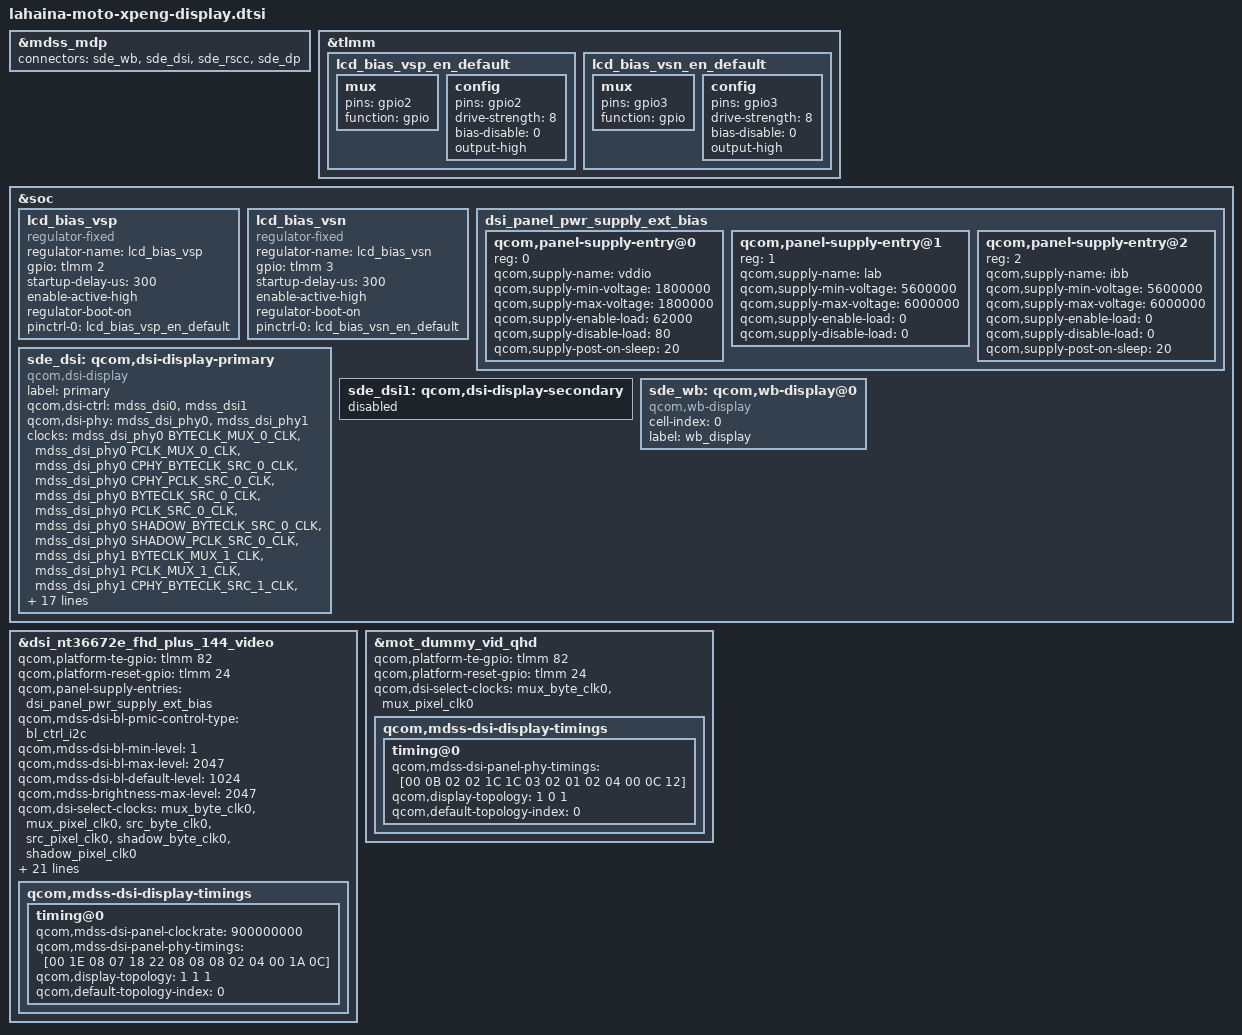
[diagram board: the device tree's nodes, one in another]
/* Copyright (c) 2019, The Linux Foundation. All rights reserved.
 *
 * This program is free software; you can redistribute it and/or modify
 * it under the terms of the GNU General Public License version 2 and
 * only version 2 as published by the Free Software Foundation.
 *
 * This program is distributed in the hope that it will be useful,
 * but WITHOUT ANY WARRANTY; without even the implied warranty of
 * MERCHANTABILITY or FITNESS FOR A PARTICULAR PURPOSE.  See the
 * GNU General Public License for more details.
 */

#include <dt-bindings/clock/mdss-5nm-pll-clk.h>
#include "dsi-panel-mot-tiamma-nt36672e-678-1080p-video-common.dtsi"
#include "dsi-panel-mot-dummy-qhd-video.dtsi"

&mdss_mdp {
	connectors = <&sde_wb &sde_dsi &sde_rscc &sde_dp>;
};


&tlmm {
	lcd_bias_vsp_en_default: lcd_bias_vsp_en_default {
		mux {
			pins = "gpio2";
			function = "gpio";
		};

		config {
			pins = "gpio2";
			drive-strength = <8>;
			bias-disable = <0>;
			output-high;
		};
	};

	lcd_bias_vsn_en_default: lcd_bias_vsn_en_default {
		mux {
			pins = "gpio3";
			function = "gpio";
		};

		config {
			pins = "gpio3";
			drive-strength = <8>;
			bias-disable = <0>;
			output-high;
		};
	};
};

&soc {
	lcd_bias_vsp: lcd_bias_vsp {
		compatible = "regulator-fixed";
		regulator-name = "lcd_bias_vsp";
		gpio = <&tlmm 2 0>;
		startup-delay-us = <300>;
		enable-active-high;
		regulator-boot-on;
		pinctrl-names = "default";
		pinctrl-0 = <&lcd_bias_vsp_en_default>;
	};

	lcd_bias_vsn: lcd_bias_vsn {
		compatible = "regulator-fixed";
		regulator-name = "lcd_bias_vsn";
		gpio = <&tlmm 3 0>;
		startup-delay-us = <300>;
		enable-active-high;
		regulator-boot-on;
		pinctrl-names = "default";
		pinctrl-0 = <&lcd_bias_vsn_en_default>;
	};

        dsi_panel_pwr_supply_ext_bias: dsi_panel_pwr_supply_ext_bias {
                #address-cells = <1>;
                #size-cells = <0>;

                qcom,panel-supply-entry@0 {
                        reg = <0>;
                        qcom,supply-name = "vddio";
                        qcom,supply-min-voltage = <1800000>;
                        qcom,supply-max-voltage = <1800000>;
                        qcom,supply-enable-load = <62000>;
                        qcom,supply-disable-load = <80>;
                        qcom,supply-post-on-sleep = <20>;
                };

                qcom,panel-supply-entry@1 {
                        reg = <1>;
                        qcom,supply-name = "lab";
                        qcom,supply-min-voltage = <5600000>;
                        qcom,supply-max-voltage = <6000000>;
                        qcom,supply-enable-load = <0>;
                        qcom,supply-disable-load = <0>;
                };

                qcom,panel-supply-entry@2 {
                        reg = <2>;
                        qcom,supply-name = "ibb";
                        qcom,supply-min-voltage = <5600000>;
                        qcom,supply-max-voltage = <6000000>;
                        qcom,supply-enable-load = <0>;
                        qcom,supply-disable-load = <0>;
                        qcom,supply-post-on-sleep = <20>;
                };
        };


	sde_dsi: qcom,dsi-display-primary {
		compatible = "qcom,dsi-display";
		label = "primary";

		qcom,dsi-ctrl = <&mdss_dsi0 &mdss_dsi1>;
		qcom,dsi-phy = <&mdss_dsi_phy0 &mdss_dsi_phy1>;

		clocks = <&mdss_dsi_phy0 BYTECLK_MUX_0_CLK>,
				 <&mdss_dsi_phy0 PCLK_MUX_0_CLK>,
				 <&mdss_dsi_phy0 CPHY_BYTECLK_SRC_0_CLK>,
				 <&mdss_dsi_phy0 CPHY_PCLK_SRC_0_CLK>,
				 <&mdss_dsi_phy0 BYTECLK_SRC_0_CLK>,
				 <&mdss_dsi_phy0 PCLK_SRC_0_CLK>,
				 <&mdss_dsi_phy0 SHADOW_BYTECLK_SRC_0_CLK>,
				 <&mdss_dsi_phy0 SHADOW_PCLK_SRC_0_CLK>,
				 <&mdss_dsi_phy1 BYTECLK_MUX_1_CLK>,
				 <&mdss_dsi_phy1 PCLK_MUX_1_CLK>,
				 <&mdss_dsi_phy1 CPHY_BYTECLK_SRC_1_CLK>,
				 <&mdss_dsi_phy1 CPHY_PCLK_SRC_1_CLK>,
				 <&mdss_dsi_phy1 BYTECLK_SRC_1_CLK>,
				 <&mdss_dsi_phy1 PCLK_SRC_1_CLK>,
				 <&mdss_dsi_phy1 SHADOW_BYTECLK_SRC_1_CLK>,
				 <&mdss_dsi_phy1 SHADOW_PCLK_SRC_1_CLK>;
		clock-names = "mux_byte_clk0", "mux_pixel_clk0",
				"cphy_byte_clk0", "cphy_pixel_clk0",
				"src_byte_clk0", "src_pixel_clk0",
				"shadow_byte_clk0", "shadow_pixel_clk0",
				"mux_byte_clk1", "mux_pixel_clk1",
				"cphy_byte_clk1", "cphy_pixel_clk1",
				"src_byte_clk1", "src_pixel_clk1",
				"shadow_byte_clk1", "shadow_pixel_clk1";

		pinctrl-names = "panel_active", "panel_suspend";
		pinctrl-0 = <&sde_dsi_active &sde_te_active>;
		pinctrl-1 = <&sde_dsi_suspend &sde_te_suspend>;

		qcom,platform-te-gpio = <&tlmm 82 0>;
		qcom,panel-te-source = <0>;

		vddio-supply = <&L12C>;
		//lab-supply = <&tps65132_outp>;
		//ibb-supply = <&tps65132_outn>;
		lab-supply = <&lcd_bias_vsp>;
		ibb-supply = <&lcd_bias_vsn>;

		qcom,mdp = <&mdss_mdp>;
		qcom,dsi-default-panel = <&dsi_nt36672e_fhd_plus_144_video>;
		qcom,platform-mot-ext-feature-enable;
		qcom,platform-mot-early-power-enable;
	};
	sde_dsi1: qcom,dsi-display-secondary {
		status = "disabled";
	};
	sde_wb: qcom,wb-display@0 {
		compatible = "qcom,wb-display";
		cell-index = <0>;
		label = "wb_display";
	};
};

&dsi_nt36672e_fhd_plus_144_video {
        qcom,platform-te-gpio = <&tlmm 82 0>;
        qcom,platform-reset-gpio = <&tlmm 24 0>;


	qcom,panel-supply-entries = <&dsi_panel_pwr_supply_ext_bias>;

	qcom,mdss-dsi-bl-pmic-control-type = "bl_ctrl_i2c";
	qcom,mdss-dsi-bl-min-level = <1>;
	qcom,mdss-dsi-bl-max-level = <2047>;
	qcom,mdss-dsi-bl-default-level = <1024>;
	qcom,mdss-brightness-max-level = <2047>;

	qcom,dsi-select-clocks = "mux_byte_clk0", "mux_pixel_clk0",
				"src_byte_clk0", "src_pixel_clk0",
				"shadow_byte_clk0", "shadow_pixel_clk0";
	qcom,dsi-supported-dfps-list = <144 120 90 60 50 48>;
	qcom,mdss-dsi-pan-enable-dynamic-fps;
	qcom,mdss-dsi-pan-fps-update = "dfps_immediate_porch_mode_vfp";
	qcom,mdss-dsi-qsync-min-refresh-rate = <48>;

	qcom,esd-check-enabled;
	qcom,mdss-dsi-panel-status-check-mode = "reg_read";
	qcom,mdss-dsi-panel-status-command = [06 01 00 01 00 00 01 0a];
	qcom,mdss-dsi-panel-status-command-state = "dsi_lp_mode";
	qcom,mdss-dsi-panel-status-value = <0x9c>;
	qcom,mdss-dsi-panel-status-read-length = <1>;
	qcom,mdss-dsi-no-panel-on-read-support;

	qcom,mdss-dsi-panel-hdr-enabled;
	qcom,mdss-dsi-panel-hdr-color-primaries = <14950 15800 34065
		15890 13475 35235 6690 2885>;
	qcom,mdss-dsi-panel-peak-brightness = <4200000>;
	qcom,mdss-dsi-panel-blackness-level = <2730>;

	qcom,mdss-dsi-display-timings {
		timing@0 {
			qcom,mdss-dsi-panel-clockrate = <900000000>;
			qcom,mdss-dsi-panel-phy-timings = [00 1E 08 07 18 22 08
				08 08 02 04 00 1A 0C];
			qcom,display-topology = <1 1 1>;
			qcom,default-topology-index = <0>;
		};
	};
};

&mot_dummy_vid_qhd {
	qcom,platform-te-gpio = <&tlmm 82 0>;
	qcom,platform-reset-gpio = <&tlmm 24 0>;

	qcom,dsi-select-clocks = "mux_byte_clk0", "mux_pixel_clk0";
	qcom,mdss-dsi-display-timings {
		timing@0 {
			qcom,mdss-dsi-panel-phy-timings = [00 0B 02 02 1C 1C 03
							02 01 02 04 00 0C 12];
			qcom,display-topology = <1 0 1>;
			qcom,default-topology-index = <0>;
		};
	};
};
